AUTOSAR XML (schema 4-2-2)
package /Components
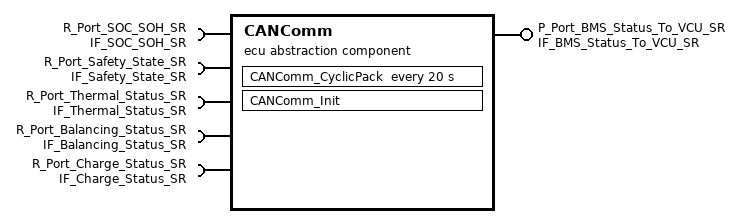
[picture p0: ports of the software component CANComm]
  ecu abstraction sw component type CANComm
    provide port P_Port_BMS_Status_To_VCU_SR: provided-interface=IF_BMS_Status_To_VCU_SR
    5 x require port:
      R_Port_SOC_SOH_SR: required-interface=IF_SOC_SOH_SR
      R_Port_Safety_State_SR: required-interface=IF_Safety_State_SR
      R_Port_Thermal_Status_SR: required-interface=IF_Thermal_Status_SR
      R_Port_Balancing_Status_SR: required-interface=IF_Balancing_Status_SR
      R_Port_Charge_Status_SR: required-interface=IF_Charge_Status_SR
    behavior CANComm_InternalBehavior
      data received event CANComm_Data_Received_Event: start-on-event=CANComm_CyclicPack
      init event CANComm_Init_Event: start-on-event=CANComm_Init
      timing event CANComm_20ms_Event: start-on-event=CANComm_CyclicPack, period=20
      runnable CANComm_Init
        data-send-points:
          access VA_Init_Send_BMS_Status_Frame: accessed-variable=P_Port_BMS_Status_To_VCU_SR.BMS_Status_Frame
          access VA_Init_Send_BMS_Diagnostics_Frame: accessed-variable=P_Port_BMS_Status_To_VCU_SR.BMS_Diagnostics_Frame
      runnable CANComm_CyclicPack: minimum-start-interval=20
        data-receive-point-by-values:
          13 x access:
            VA_Cyc_Read_PackSOC: accessed-variable=R_Port_SOC_SOH_SR.PackSOC
            VA_Cyc_Read_PackSOH: accessed-variable=R_Port_SOC_SOH_SR.PackSOH
            VA_Cyc_Read_SafetyState: accessed-variable=R_Port_Safety_State_SR.SafetyState
            VA_Cyc_Read_FaultCode: accessed-variable=R_Port_Safety_State_SR.FaultCode
            VA_Cyc_Read_CoolantPumpSpeed: accessed-variable=R_Port_Thermal_Status_SR.CoolantPumpSpeed
            VA_Cyc_Read_FanSpeed: accessed-variable=R_Port_Thermal_Status_SR.FanSpeed
            VA_Cyc_Read_ThermalFault: accessed-variable=R_Port_Thermal_Status_SR.ThermalFault
            VA_Cyc_Read_BalancingActive: accessed-variable=R_Port_Balancing_Status_SR.BalancingActive
            VA_Cyc_Read_MaxDeltaVoltage: accessed-variable=R_Port_Balancing_Status_SR.MaxDeltaVoltage
            VA_Cyc_Read_BalancingFault: accessed-variable=R_Port_Balancing_Status_SR.BalancingFault
            VA_Cyc_Read_ChargeMode: accessed-variable=R_Port_Charge_Status_SR.ChargeMode
            VA_Cyc_Read_ChargeCurrentSetpoint: accessed-variable=R_Port_Charge_Status_SR.ChargeCurrentSetpoint
            VA_Cyc_Read_ChargeFault: accessed-variable=R_Port_Charge_Status_SR.ChargeFault
        data-send-points:
          access VA_Cyc_Send_BMS_Status_Frame: accessed-variable=P_Port_BMS_Status_To_VCU_SR.BMS_Status_Frame
          access VA_Cyc_Send_BMS_Diagnostics_Frame: accessed-variable=P_Port_BMS_Status_To_VCU_SR.BMS_Diagnostics_Frame
